# ATSAM4C32E_1 register map
Vendor: Atmel; Series: SAM4C; File version: 0
Atmel ATSAM4C32E Microcontroller
CPU: CM4 r0p0, selectable endian, no MPU, FPU, 4 interrupt priority bits
Registers are 32-bit, read-write, reset 0x0 unless marked. A register's access mark holds for its fields unless they carry their own. Offsets are from the block's base; lines under a group give offsets from that group; [hi:lo] are bit positions; {n}, {i} and the like mark numbered series; 'fields as' and 'values as' point back to an identical list; <NAME> marks a mode.

## Memory map
0x40000000 AES size 0x4000 — Advanced Encryption Standard
0x40008000 SPI0 size 0x4000 — Serial Peripheral Interface 0
0x40010000 TC0 size 0x4000 — Timer Counter 0
0x40014000 TC1 size 0x4000 — Timer Counter 1
0x40018000 TWI0 size 0x4000 — Two-wire Interface 0
0x4001C000 TWI1 size 0x4000 — Two-wire Interface 1
0x40020000 UOTGHS size 0x4000 — USB On-The-Go Interface
0x40024000 USART0 size 0x4000 — Universal Synchronous Asynchronous Receiver Transmitter 0
0x40028000 USART1 size 0x4000 — Universal Synchronous Asynchronous Receiver Transmitter 1
0x4002C000 USART2 size 0x4000 — Universal Synchronous Asynchronous Receiver Transmitter 2
0x40030000 USART3 size 0x4000 — Universal Synchronous Asynchronous Receiver Transmitter 3
0x40034000 USART4 size 0x4000 — Universal Synchronous Asynchronous Receiver Transmitter 4
0x40038000 ADC size 0x4000 — Analog-to-Digital Converter
0x4003C000 SLCDC size 0x4000 — Segment LCD Controller
0x40044000 ICM size 0x4000 — Integrity Check Monitor
0x40048000 TRNG size 0x4000 — True Random Number Generator
0x4004C000 IPC0 size 0x4000 — Interprocessor Communication 0
0x4007C000 CMCC0 size 0x4000 — Cortex M Cache Controller 0
0x400E0000 SMC0 size 0x200 — Static Memory Controller 0
0x400E0200 MATRIX0 size 0x200 — AHB Bus Matrix 0
0x400E0400 PMC size 0x200 — Power Management Controller
0x400E0600 UART0 size 0x140 — Universal Asynchronous Receiver Transmitter 0
0x400E0740 CHIPID size 0xC0 — Chip Identifier
0x400E0A00 EFC0 size 0x200 — Embedded Flash Controller 0
0x400E0C00 EFC1 size 0x200 — Embedded Flash Controller 1
0x400E0E00 PIOA size 0x200 — Parallel Input/Output Controller A
0x400E1000 PIOB size 0x200 — Parallel Input/Output Controller B
0x400E1200 PIOD size 0x200 — Parallel Input/Output Controller D
0x400E1400 RSTC size 0x200 — Reset Controller
0x400E1410 SUPC size 0x200 — Supply Controller
0x400E1430 RTT size 0x200 — Real-time Timer
0x400E1450 WDT size 0x200 — Watchdog Timer
0x400E1460 RTC size 0x200 — Real-time Clock
0x400E1490 GPBR size 0x200 — General Purpose Backup Registers
0x400E1500 RSWDT size 0x200 — Reinforced Safety Watchdog Timer
0x48000000 SPI1 size 0x4000 — Serial Peripheral Interface 1
0x48004000 UART1 size 0x4000 — Universal Asynchronous Receiver Transmitter 1
0x48008000 PWM size 0x4000 — Pulse Width Modulation Controller
0x4800C000 PIOC size 0x4000 — Parallel Input/Output Controller C
0x48010000 MATRIX1 size 0x4000 — AHB Bus Matrix 1
0x48014000 IPC1 size 0x4000 — Interprocessor Communication 1
0x48018000 CMCC1 size 0x4000 — Cortex M Cache Controller 1
0x4801C000 SMC1 size 0x4000 — Static Memory Controller 1

## Interrupts
5 PMC
6 EFC0
7 EFC1
8 UART0
11 PIOA
12 PIOB
13 PIOD
14 USART0
15 USART1
16 USART2
17 USART3
18 USART4
19 TWI0
20 TWI1
21 SPI0
22 UOTGHS
23 TC0
24 TC1 (TC0)
25 TC2 (TC0)
26 TC3 (TC1)
27 TC4 (TC1)
28 TC5 (TC1)
29 ADC
31 IPC0
32 SLCDC
33 TRNG
34 ICM
36 AES
37 PIOC
38 UART1
39 IPC1
40 SPI1
41 PWM

## ICM — Integrity Check Monitor
Base 0x40044000; register names take the prefix ICM_
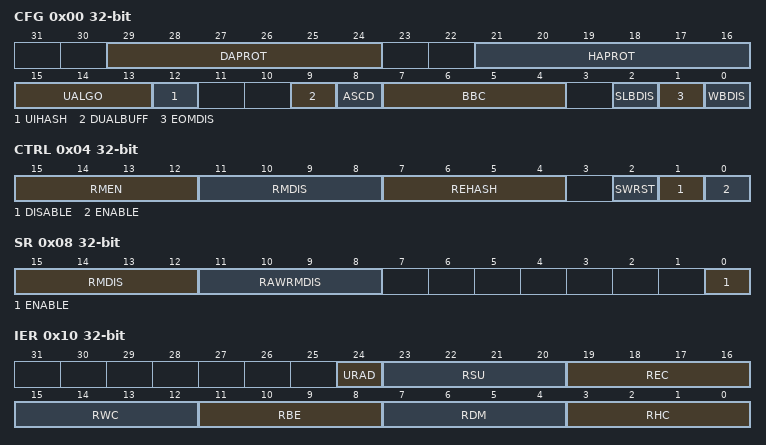
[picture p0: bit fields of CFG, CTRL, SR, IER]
0x00 CFG — Configuration Register
  [29:24] DAPROT — Region Descriptor Area Protection
  [21:16] HAPROT — Region Hash Area Protection
  [15:13] UALGO — User SHA Algorithm
    0=SHA1 (SHA1 algorithm processed); 1=SHA256 (SHA256 algorithm processed); 4=SHA224 (SHA224 algorithm processed)
  [12] UIHASH — User Initial Hash Value
  [9] DUALBUFF — Dual Input Buffer
  [8] ASCD — Automatic Switch To Compare Digest
  [7:4] BBC — Bus Burden Control
  [2] SLBDIS — Secondary List Branching Disable
  [1] EOMDIS — End of Monitoring Disable
  [0] WBDIS — Write Back Disable
0x04 CTRL wo reset not defined — Control Register
  [15:12] RMEN — Region Monitoring Enable
  [11:8] RMDIS — Region Monitoring Disable
  [7:4] REHASH — Recompute Internal Hash
  [2] SWRST — Software Reset
  [1] DISABLE — ICM Disable Register
  [0] ENABLE — ICM Enable
0x08 SR wo — Status Register
  [15:12] RMDIS — Region Monitoring Disabled Status
  [11:8] RAWRMDIS — RAW Region Monitoring Disabled Status
  [0] ENABLE — ICM Controller Enable Register
0x10 IER wo reset not defined — Interrupt Enable Register
  [24] URAD — Undefined Register Access Detection Interrupt Enable
  [23:20] RSU — Region Status Updated Interrupt Disable
  [19:16] REC — Region End bit Condition Detected Interrupt Enable
  [15:12] RWC — Region Wrap Condition detected Interrupt Enable
  [11:8] RBE — Region Bus Error Interrupt Enable
  [7:4] RDM — Region Digest Mismatch Interrupt Enable
  [3:0] RHC — Region Hash Completed Interrupt Enable
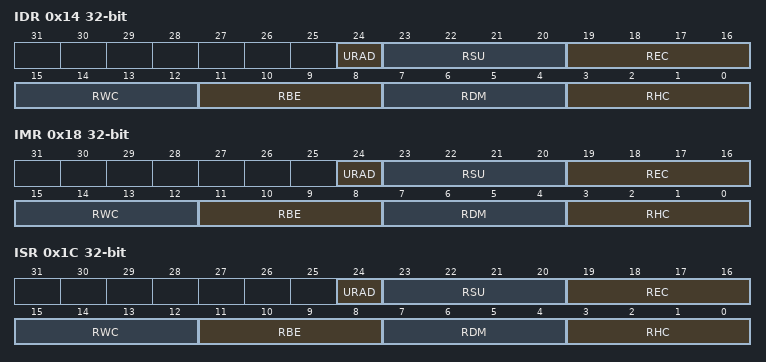
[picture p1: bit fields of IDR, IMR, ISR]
0x14 IDR wo reset not defined — Interrupt Disable Register
  [24] URAD — Undefined Register Access Detection Interrupt Disable
  [23:20] RSU — Region Status Updated Interrupt Disable
  [19:16] REC — Region End bit Condition detected Interrupt Disable
  [15:12] RWC — Region Wrap Condition Detected Interrupt Disable
  [11:8] RBE — Region Bus Error Interrupt Disable
  [7:4] RDM — Region Digest Mismatch Interrupt Disable
  [3:0] RHC — Region Hash Completed Interrupt Disable
0x18 IMR ro — Interrupt Mask Register
  [24] URAD — Undefined Register Access Detection Interrupt Mask
  [23:20] RSU — Region Status Updated Interrupt Mask
  [19:16] REC — Region End bit Condition Detected Interrupt Mask
  [15:12] RWC — Region Wrap Condition Detected Interrupt Mask
  [11:8] RBE — Region Bus Error Interrupt Mask
  [7:4] RDM — Region Digest Mismatch Interrupt Mask
  [3:0] RHC — Region Hash Completed Interrupt Mask
0x1C ISR ro — Interrupt Status Register
  [24] URAD — Undefined Register Access Detection Status
  [23:20] RSU — Region Status Updated Detected
  [19:16] REC — Region End bit Condition Detected
  [15:12] RWC — Region Wrap Condition Detected
  [11:8] RBE — Region Bus Error
  [7:4] RDM — Region Digest Mismatch
  [3:0] RHC — Region Hash Completed
0x20 UASR ro — Undefined Access Status Register
  [2:0] URAT — Undefined Register Access Trace
    0=UNSPEC_STRUCT_MEMBER (Unspecified structure member set to one detected when the descriptor is loaded.); 1=ICM_CFG_MODIFIED (ICM_CFG modified during active monitoring.); 2=ICM_DSCR_MODIFIED (ICM_DSCR modified during active monitoring.); 3=ICM_HASH_MODIFIED (ICM_HASH modified during active monitoring); 4=READ_ACCESS (Write-only register read access)
0x30 DSCR — Region Descriptor Area Start Address Register
  [31:6] DASA — Descriptor Area Start Address
0x34 HASH — Region Hash Area Start Address Register
  [31:7] HASA — Hash Area Start Address
{0x38+4i} UIHVAL[{i}] (i=0..7) wo reset not defined — User Initial Hash Value 0 Register
  [31:0] VAL — Initial Hash Value

## Notices in the file
SAM Software Package License
Copyright (c) 2014, Atmel Corporation
All rights reserved.
Redistribution and use in source and binary forms, with or without
modification, are permitted provided that the following condition is met:
- Redistributions of source code must retain the above copyright notice,
this list of conditions and the disclaimer below.
Atmel's name may not be used to endorse or promote products derived from
this software without specific prior written permission.
DISCLAIMER:  THIS SOFTWARE IS PROVIDED BY ATMEL "AS IS" AND ANY EXPRESS OR
IMPLIED WARRANTIES, INCLUDING, BUT NOT LIMITED TO, THE IMPLIED WARRANTIES OF
MERCHANTABILITY, FITNESS FOR A PARTICULAR PURPOSE AND NON-INFRINGEMENT ARE
DISCLAIMED. IN NO EVENT SHALL ATMEL BE LIABLE FOR ANY DIRECT, INDIRECT,
INCIDENTAL, SPECIAL, EXEMPLARY, OR CONSEQUENTIAL DAMAGES (INCLUDING, BUT NOT
LIMITED TO, PROCUREMENT OF SUBSTITUTE GOODS OR SERVICES; LOSS OF USE, DATA,
OR PROFITS; OR BUSINESS INTERRUPTION) HOWEVER CAUSED AND ON ANY THEORY OF
LIABILITY, WHETHER IN CONTRACT, STRICT LIABILITY, OR TORT (INCLUDING
NEGLIGENCE OR OTHERWISE) ARISING IN ANY WAY OUT OF THE USE OF THIS SOFTWARE,
EVEN IF ADVISED OF THE POSSIBILITY OF SUCH DAMAGE.
